VERSION ""

NS_ :

BS_:

BU_: FCU CAP

BO_ 2553259969 Unit_ID: 1 CAP
 SG_ UnitID : 0|8@1+ (1,0) [0|3] ""  FCU

BO_ 2552342465 FeedBack_Life_CT_FC_WC: 8 CAP
 SG_ FactoryWarning : 52|1@1+ (1,0) [0|1] ""  FCU
 SG_ MotorOverTemperature : 31|1@1+ (1,0) [0|1] ""  FCU
 SG_ InvalidModel : 30|1@1+ (1,0) [0|1] ""  FCU
 SG_ PowerDownError : 29|1@1+ (1,0) [0|1] ""  FCU
 SG_ CommunicationHeartBeatFault : 28|1@1+ (1,0) [0|1] ""  FCU
 SG_ FactoryFault : 27|1@1+ (1,0) [0|1] ""  FCU
 SG_ IGBTCOverTemperature : 26|1@1+ (1,0) [0|1] ""  FCU
 SG_ IGBTBOverTemperature : 25|1@1+ (1,0) [0|1] ""  FCU
 SG_ IGBTAOverTemperature : 24|1@1+ (1,0) [0|1] ""  FCU
 SG_ ControllerOverTemperature : 23|1@1+ (1,0) [0|1] ""  FCU
 SG_ MotorOverSpeed : 22|1@1+ (1,0) [0|1] ""  FCU
 SG_ MotorOverCurrent : 21|1@1+ (1,0) [0|1] ""  FCU
 SG_ DCLinkUnderVoltage : 20|1@1+ (1,0) [0|1] ""  FCU
 SG_ DCLinkOverVoltage : 19|1@1+ (1,0) [0|1] ""  FCU
 SG_ HWOverCurrentC : 18|1@1+ (1,0) [0|1] ""  FCU
 SG_ HWOverCurrentB : 17|1@1+ (1,0) [0|1] ""  FCU
 SG_ HWOverCurrentA : 16|1@1+ (1,0) [0|1] ""  FCU
 SG_ DC_ChopperActive : 50|1@1+ (1,0) [0|1] ""  FCU
 SG_ HighMotorTemperature : 51|1@1+ (1,0) [0|1] ""  FCU
 SG_ HighIGBT_C_Temperature : 49|1@1+ (1,0) [0|1] ""  FCU
 SG_ HighIGBT_B_Temperature : 48|1@1+ (1,0) [0|1] ""  FCU
 SG_ HighIGBT_A_Temperature : 47|1@1+ (1,0) [0|1] ""  FCU
 SG_ HighAmbientTemperature : 46|1@1+ (1,0) [0|1] ""  FCU
 SG_ CurrentLimit : 45|1@1+ (1,0) [0|1] ""  FCU
 SG_ HighMotorCurrent : 44|1@1+ (1,0) [0|1] ""  FCU
 SG_ LowMotorSpeed : 43|1@1+ (1,0) [0|1] ""  FCU
 SG_ HighMotorSpeed : 42|1@1+ (1,0) [0|1] ""  FCU
 SG_ Low_DC_Link : 41|1@1+ (1,0) [0|1] ""  FCU
 SG_ High_DC_Link : 40|1@1+ (1,0) [0|1] ""  FCU
 SG_ ControllerTemperature : 8|8@1+ (1,-40) [-40|85] "℃"  FCU
 SG_ life : 0|8@1+ (1,0) [0|255] ""  FCU

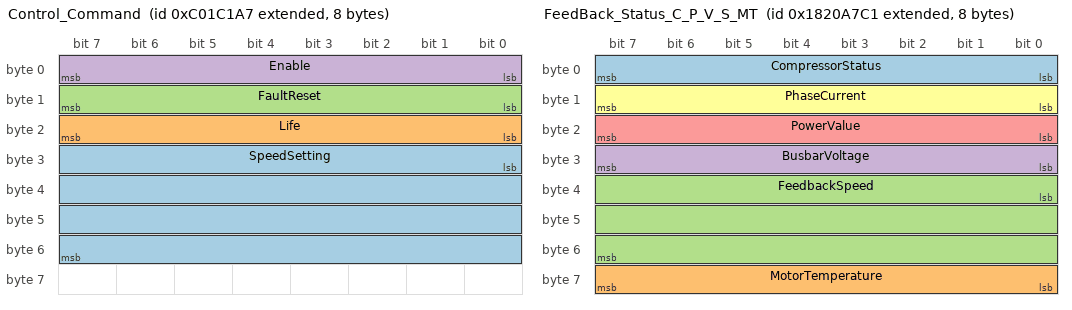
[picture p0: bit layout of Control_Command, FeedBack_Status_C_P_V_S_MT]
BO_ 2348925351 Control_Command: 8 FCU
 SG_ SpeedSetting : 24|32@1+ (1,0) [30000|120000] "rpm"  CAP
 SG_ Life : 16|8@1+ (1,0) [0|255] ""  CAP
 SG_ FaultReset : 8|8@1+ (1,0) [0|1] ""  CAP
 SG_ Enable : 0|8@1+ (1,0) [0|1] ""  CAP

BO_ 2552276929 FeedBack_Status_C_P_V_S_MT: 8 CAP
 SG_ CompressorStatus : 0|8@1+ (1,0) [0|1] ""  FCU
 SG_ MotorTemperature : 56|8@1+ (1,-40) [-40|180] "℃"  FCU
 SG_ FeedbackSpeed : 32|24@1+ (1,0) [0|120000] "rpm"  FCU
 SG_ BusbarVoltage : 24|8@1+ (3,0) [300|750] "3V"  FCU
 SG_ PowerValue : 16|8@1+ (100,-4000) [-4000|21500] "W"  FCU
 SG_ PhaseCurrent : 8|8@1+ (1,-40) [-40|65] "A"  FCU

CM_ SG_ 2553259969 UnitID "控制器编号";
CM_ SG_ 2552342465 FactoryWarning "保留工厂警告";
CM_ SG_ 2552342465 MotorOverTemperature "压气机超温度故障";
CM_ SG_ 2552342465 InvalidModel "无效指令故障";
CM_ SG_ 2552342465 PowerDownError "关机错误";
CM_ SG_ 2552342465 CommunicationHeartBeatFault "rolling counter异常故障";
CM_ SG_ 2552342465 FactoryFault "保留工厂故障";
CM_ SG_ 2552342465 IGBTCOverTemperature "C相超温度故障";
CM_ SG_ 2552342465 IGBTBOverTemperature "B相超温度故障";
CM_ SG_ 2552342465 IGBTAOverTemperature "A相超温度故障";
CM_ SG_ 2552342465 ControllerOverTemperature "控制器超温度故障";
CM_ SG_ 2552342465 MotorOverSpeed "空压机运转超速故障";
CM_ SG_ 2552342465 MotorOverCurrent "控制器输出超电流故障";
CM_ SG_ 2552342465 DCLinkUnderVoltage "直流欠压故障";
CM_ SG_ 2552342465 DCLinkOverVoltage "直流超电压故障";
CM_ SG_ 2552342465 HWOverCurrentC "C相超电流故障";
CM_ SG_ 2552342465 HWOverCurrentB "B相超电流故障";
CM_ SG_ 2552342465 HWOverCurrentA "A相超电流故障";
CM_ SG_ 2552342465 DC_ChopperActive "直流斩波器激活状态警告";
CM_ SG_ 2552342465 HighMotorTemperature "压气机温度偏高警告";
CM_ SG_ 2552342465 HighIGBT_C_Temperature "IGBT C 温度偏高警告";
CM_ SG_ 2552342465 HighIGBT_B_Temperature "IGBT B 温度偏高警告";
CM_ SG_ 2552342465 HighIGBT_A_Temperature "IGBT A 温度偏高警告";
CM_ SG_ 2552342465 HighAmbientTemperature "控制器温度偏高警告";
CM_ SG_ 2552342465 CurrentLimit "电流上限值";
CM_ SG_ 2552342465 HighMotorCurrent "电流接近最大值警告";
CM_ SG_ 2552342465 LowMotorSpeed "速度低于怠速警告";
CM_ SG_ 2552342465 HighMotorSpeed "速度接近最大警告";
CM_ SG_ 2552342465 Low_DC_Link "电压接近最低电压警告";
CM_ SG_ 2552342465 High_DC_Link "电压接近最高电压警告";
CM_ SG_ 2552342465 ControllerTemperature "控制器温度";
CM_ SG_ 2552342465 life "life";
CM_ SG_ 2348925351 SpeedSetting "转速设定";
CM_ SG_ 2348925351 Life "Life";
CM_ SG_ 2348925351 FaultReset "故障复位";
CM_ SG_ 2348925351 Enable "使能";
CM_ SG_ 2552276929 CompressorStatus "空压机状态";
CM_ SG_ 2552276929 MotorTemperature "泵头温度";
CM_ SG_ 2552276929 FeedbackSpeed "反馈转速";
CM_ SG_ 2552276929 BusbarVoltage "母线电压";
CM_ SG_ 2552276929 PowerValue "功率";
CM_ SG_ 2552276929 PhaseCurrent "相电流";
BA_DEF_ SG_  "GenSigStartValue" INT -2147483648 2147483647;
BA_DEF_  "Baudrate" ENUM  "125k","250k","500k";
BA_DEF_ BO_  "GenMsgSendType" ENUM  "Cycle","Spontaneous If Active","vector_leerstring";
BA_DEF_ BO_  "GenMsgCycleTime" INT 0 5000;
BA_DEF_  "BusType" STRING ;
BA_DEF_DEF_  "GenSigStartValue" 0;
BA_DEF_DEF_  "Baudrate" "500k";
BA_DEF_DEF_  "GenMsgSendType" "Cycle";
BA_DEF_DEF_  "GenMsgCycleTime" 0;
BA_DEF_DEF_  "BusType" "";
BA_ "BusType" "CAN";
BA_ "Baudrate" 1;
BA_ "GenMsgCycleTime" BO_ 2553259969 100;
BA_ "GenMsgCycleTime" BO_ 2552342465 100;
BA_ "GenMsgCycleTime" BO_ 2348925351 100;
BA_ "GenMsgCycleTime" BO_ 2552276929 100;
BA_ "GenSigStartValue" SG_ 2552342465 ControllerTemperature 40;
BA_ "GenSigStartValue" SG_ 2348925351 SpeedSetting 30000;
BA_ "GenSigStartValue" SG_ 2552276929 MotorTemperature 40;
BA_ "GenSigStartValue" SG_ 2552276929 BusbarVoltage 100;
BA_ "GenSigStartValue" SG_ 2552276929 PowerValue 40;
BA_ "GenSigStartValue" SG_ 2552276929 PhaseCurrent 40;
VAL_ 2553259969 UnitID 3 "Compressor'" ;
VAL_ 2348925351 FaultReset 1 "Reset" 0 "No Operation" ;
VAL_ 2348925351 Enable 1 "Run" 0 "Disable" ;
VAL_ 2552276929 CompressorStatus 1 "Run" 0 "Disable" ;
